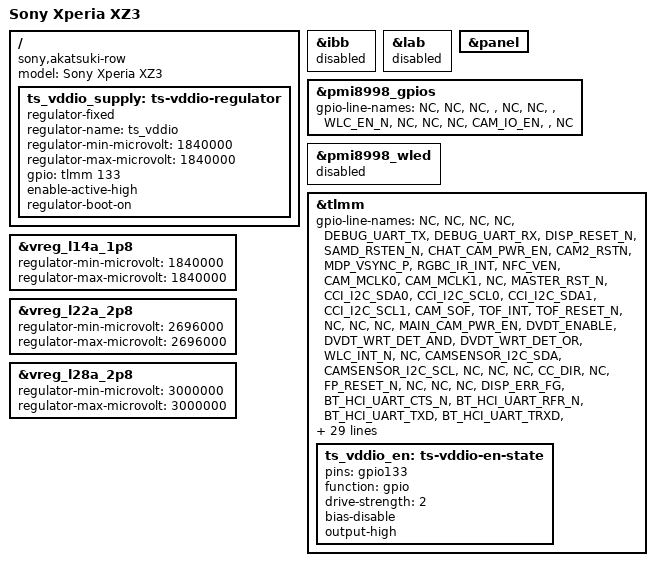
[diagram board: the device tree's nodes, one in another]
// SPDX-License-Identifier: BSD-3-Clause
/*
 * Copyright (c) 2021, Konrad Dybcio <konrad.dybcio@somainline.org>
 */

/dts-v1/;

#include "sdm845-sony-xperia-tama.dtsi"

/* XZ3 uses an Atmel touchscreen instead. */
/delete-node/ &touchscreen;

/ {
	model = "Sony Xperia XZ3";
	compatible = "sony,akatsuki-row", "qcom,sdm845";

	/* Fixed DCDC for the OLED panel */
	ts_vddio_supply: ts-vddio-regulator {
		compatible = "regulator-fixed";
		regulator-name = "ts_vddio";

		regulator-min-microvolt = <1840000>;
		regulator-max-microvolt = <1840000>;

		gpio = <&tlmm 133 GPIO_ACTIVE_HIGH>;
		enable-active-high;
		regulator-boot-on;
	};
};

&ibb {
	status = "disabled";
};

&lab {
	status = "disabled";
};

&panel {
	/* Akatsuki uses an OLED panel. */
	/delete-property/ backlight;
	/delete-property/ vsp-supply;
	/delete-property/ vsn-supply;
	/delete-property/ touch-reset-gpios;
};

&pmi8998_gpios {
	gpio-line-names = "NC", /* GPIO_1 */
			  "NC",
			  "NC",
			  "",
			  "NC",
			  "NC",
			  "",
			  "WLC_EN_N",
			  "NC",
			  "NC", /* GPIO_10 */
			  "NC",
			  "CAM_IO_EN",
			  "",
			  "NC";
};

&pmi8998_wled {
	status = "disabled";
};

&tlmm {
	gpio-line-names = "NC", /* GPIO_0 */
			  "NC",
			  "NC",
			  "NC",
			  "DEBUG_UART_TX",
			  "DEBUG_UART_RX",
			  "DISP_RESET_N",
			  "SAMD_RSTEN_N",
			  "CHAT_CAM_PWR_EN",
			  "CAM2_RSTN",
			  "MDP_VSYNC_P", /* GPIO_10 */
			  "RGBC_IR_INT",
			  "NFC_VEN",
			  "CAM_MCLK0",
			  "CAM_MCLK1",
			  "NC",
			  "MASTER_RST_N",
			  "CCI_I2C_SDA0",
			  "CCI_I2C_SCL0",
			  "CCI_I2C_SDA1",
			  "CCI_I2C_SCL1", /* GPIO_20 */
			  "CAM_SOF",
			  "TOF_INT",
			  "TOF_RESET_N",
			  "NC",
			  "NC",
			  "NC",
			  "MAIN_CAM_PWR_EN",
			  "DVDT_ENABLE",
			  "DVDT_WRT_DET_AND",
			  "DVDT_WRT_DET_OR", /* GPIO_30 */
			  "WLC_INT_N",
			  "NC",
			  "CAMSENSOR_I2C_SDA",
			  "CAMSENSOR_I2C_SCL",
			  "NC",
			  "NC",
			  "NC",
			  "CC_DIR",
			  "NC",
			  "FP_RESET_N", /* GPIO_40 */
			  "NC",
			  "NC",
			  "NC",
			  "DISP_ERR_FG",
			  "BT_HCI_UART_CTS_N",
			  "BT_HCI_UART_RFR_N",
			  "BT_HCI_UART_TXD",
			  "BT_HCI_UART_TRXD",
			  "USB_AUDIO_EN1",
			  "SW_SERVICE", /* GPIO_50 */
			  "US_EURO_SEL",
			  "SAMD_BOOTL_PIN",
			  "CODEC_INT2_N",
			  "CODEC_INT1_N",
			  "APPS_I2C_SDA",
			  "APPS_I2C_SCL",
			  "FORCED_USB_BOOT",
			  "SDM_SWD_CLK",
			  "SDM_SWD_DAT",
			  "SAMD_RST", /* GPIO_60 */
			  "USB_PD_EN",
			  "NFC_DWLD_EN",
			  "NFC_IRQ",
			  "CODEC_RST_N",
			  "CODEC_SPI_MISO",
			  "CODEC_SPI_MOSI",
			  "CODEC_SPI_CLK",
			  "CODEC_SPI_CS_N",
			  "NC",
			  "CODEC_SLIMBUS_CLK", /* GPIO_70 */
			  "CODEC_SLIMBUS_DATA0",
			  "CODEC_SLIMBUS_DATA1",
			  "BT_FM_SLIMBUS_DATA",
			  "BT_FM_SLIMBUS_CLK",
			  "HW_ID_0",
			  "HW_ID_1",
			  "TX_GTR_THRES_IN",
			  "MODE_SEL2",
			  "NC",
			  "CAM1_RSTN", /* GPIO_80 */
			  "",
			  "",
			  "",
			  "",
			  "TS_I2C_SDA",
			  "TS_I2C_SCL",
			  "NC",
			  "NC",
			  "NC",
			  "NC", /* GPIO_90 */
			  "NC",
			  "NC",
			  "NC",
			  "NC",
			  "NC",
			  "NC",
			  "RFFE6_CLK",
			  "RFFE6_DATA",
			  "TS_RESET_N",
			  "", /* GPIO_100 */
			  "GRFC4",
			  "DEBUG_GPIO0",
			  "DEBUG_GPIO1",
			  "RF_LCD_ID_EN",
			  "UIM2_DATA",
			  "UIM2_CLK",
			  "UIM2_RESET",
			  "UIM2_PRESENT",
			  "UIM1_DATA",
			  "UIM1_CLK", /* GPIO_110 */
			  "UIM1_RESET",
			  "UIM1_PRESENT",
			  "NC",
			  "NC",
			  "NC",
			  "NFC_ESE_PWR_REQ",
			  "ACCEL_INT",
			  "GYRO_INT",
			  "COMPASS_INT",
			  "ALS_PROX_INT_N", /* GPIO_120 */
			  "FP_INT",
			  "RF_ID_EXTENTION",
			  "BAROMETER_INT",
			  "ACC_COVER_OPEN",
			  "TS_INT_N",
			  "TRAY_DET",
			  "GRFC3",
			  "NC",
			  "UIM2_DETECT_EN",
			  "QLINK_REQUEST", /* GPIO_130 */
			  "QLINK_ENABLE",
			  "GRFC2",
			  "TS_VDDIO_EN",
			  "WMSS_RESET_N",
			  "PA_INDICATOR_OR",
			  "GRFC1",
			  "RFFE3_DATA",
			  "RFFE3_CLK",
			  "RFFE4_DATA",
			  "RFFE4_CLK", /* GPIO_140 */
			  "RFFE5_DATA",
			  "RFFE5_CLK",
			  "GNSS_EN",
			  "MSS_LTE_COXM_TXD",
			  "MSS_LTE_COXM_RXD",
			  "RFFE2_DATA",
			  "RFFE2_CLK",
			  "RFFE1_DATA",
			  "RFFE1_CLK";

	ts_vddio_en: ts-vddio-en-state {
		pins = "gpio133";
		function = "gpio";
		drive-strength = <2>;
		bias-disable;
		output-high;
	};
};

&vreg_l14a_1p8 {
	regulator-min-microvolt = <1840000>;
	regulator-max-microvolt = <1840000>;
};

&vreg_l22a_2p8 {
	/* Note: Round-down from 2700000 to be a multiple of PLDO step-size 8000 */
	regulator-min-microvolt = <2696000>;
	regulator-max-microvolt = <2696000>;
};

&vreg_l28a_2p8 {
	regulator-min-microvolt = <3000000>;
	regulator-max-microvolt = <3000000>;
};
